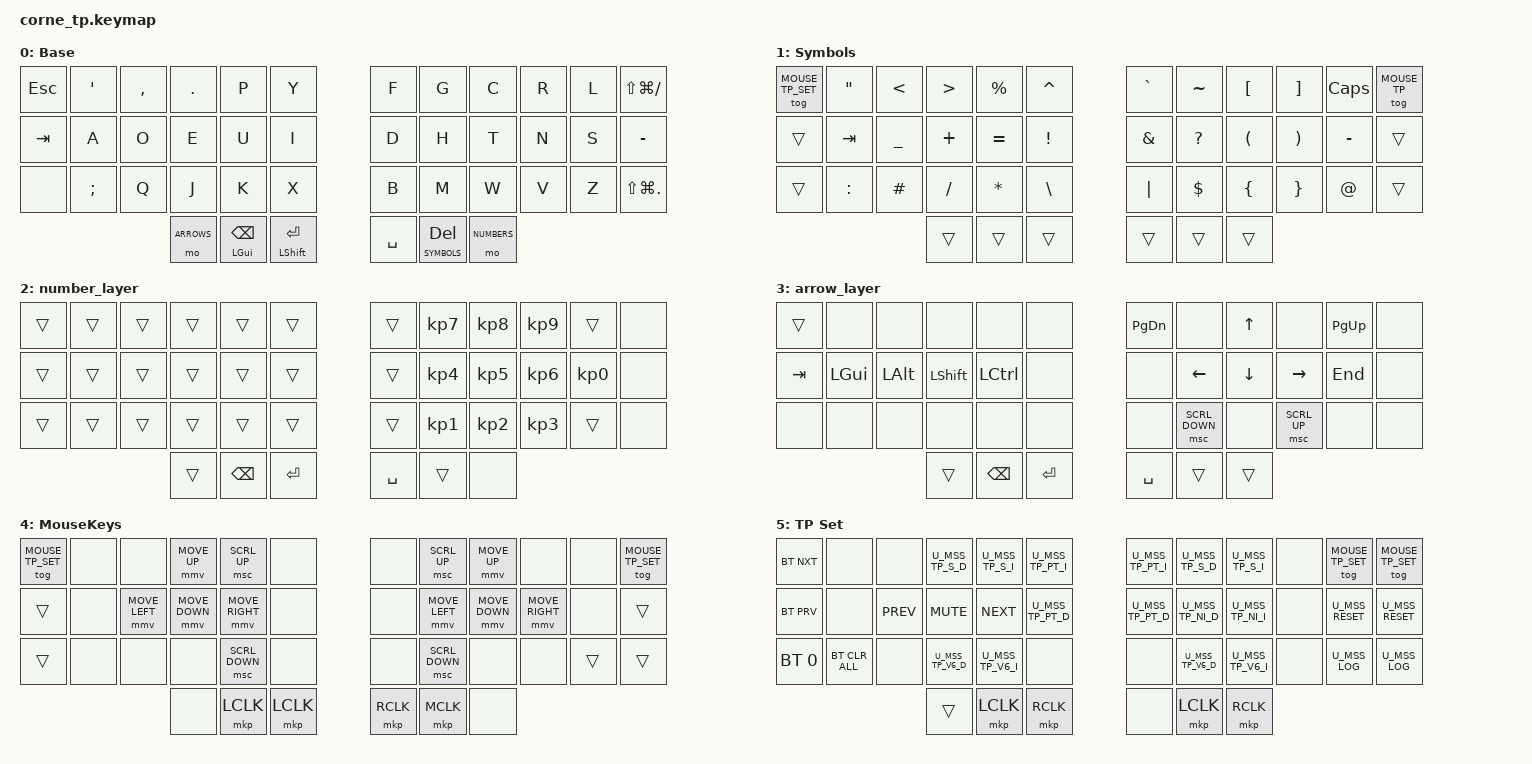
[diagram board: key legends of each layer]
/*
 * Copyright (c) 2020 The ZMK Contributors
 *
 * SPDX-License-Identifier: MIT
 */

#include <behaviors.dtsi>
#include <dt-bindings/zmk/keys.h>
#include <dt-bindings/zmk/bt.h>

#define BASE 0
#define SYMBOLS 1
#define NUMBERS 2
#define ARROWS 3
#define MOUSE_TP 4
#define MOUSE_TP_SET 5 //include things like bluetooth set, volume, next, etc. here?

/*
 * Defines to enable/disable features
 *
 * These defines allow us to conditionally enable and disable parts of the keymap config.
 *
 * For example, if we decide to build the firmware without the mouse features, we can
 * disable all the config options that rely on those forks and modules without having
 * to edit the entire keymap file manually every time.
 */

#define HAS_MOUSE_KEYS
#define HAS_MOUSE_TP

#ifdef HAS_MOUSE_KEYS
  #include <dt-bindings/zmk/mouse.h>
  #include <behaviors/mouse_keys.dtsi>
#endif  // HAS_MOUSE_KEYS

#ifdef HAS_MOUSE_TP
  // We store the trackpoint settings in a separate file
  // to make organization a little easier.
  #include "include/mouse_tp.dtsi"
#endif  // HAS_MOUSE_TP


#ifdef HAS_MOUSE_TP
  #define U_TOG_TP_SET &tog MOUSE_TP_SET
#else
  #define U_TOG_TP_SET &none
#endif  // HAS_MOUSE_TP

// Disable line-wrap in your editor to see a "visualization" of the key layouts
/ {

  keymap {
    compatible = "zmk,keymap";

    Base_layer {
      display-name = "Base";
      bindings = <
// ╭────────────────────────┬────────────────────────┬────────────────────────┬────────────────────────┬────────────────────────┬────────────────────────╮    ╭────────────────────────┬────────────────────────┬────────────────────────┬───────────────────────┬────────────────────────┬────────────────────────╮
     &kp ESC                  &kp SQT                  &kp COMMA                &kp DOT                  &kp P                    &kp Y                         &kp F                    &kp G                    &kp C                    &kp R                    &kp L                    &kp LS(LG(SLASH))
// ├────────────────────────┼────────────────────────┼────────────────────────┼────────────────────────┼────────────────────────┼────────────────────────┤    ├────────────────────────┼────────────────────────┼────────────────────────┼───────────────────────┼────────────────────────┼────────────────────────┤
     &kp TAB                  &kp A                    &kp O                    &kp E                    &kp U                    &kp I                         &kp D                    &kp H                    &kp T                    &kp N                    &kp S                    &kp MINUS
// ├────────────────────────┼────────────────────────┼────────────────────────┼────────────────────────┼────────────────────────┼────────────────────────┤    ├────────────────────────┼────────────────────────┼────────────────────────┼───────────────────────┼────────────────────────┼────────────────────────┤
     &none                    &kp SEMI                 &kp Q                    &kp J                    &kp K                    &kp X                         &kp B                    &kp M                    &kp W                    &kp V                    &kp Z                    &kp LS(LG(DOT))
// ╰────────────────────────┴────────────────────────┴────────────────────────┴────────────────────────┼────────────────────────┼────────────────────────┤    ├────────────────────────┼────────────────────────┼────────────────────────┼───────────────────────┼────────────────────────┼────────────────────────╯
                                                                                &mo ARROWS                &mt LEFT_GUI BSPC       &mt LSHIFT RET                 &kp SPACE                 &lt SYMBOLS DEL                  &mo NUMBERS
//           U_THUMB_INNER                                                                 ╰────────────────────────┴────────────────────────┴────────────────────────╯    ╰────────────────────────┴────────────────────────┴────────────────────────╯

      >;
    };


    Lower_layer {
      display-name = "Symbols";
      bindings = <
// ╭────────────────────────┬────────────────────────┬────────────────────────┬────────────────────────┬────────────────────────┬────────────────────────╮    ╭────────────────────────┬────────────────────────┬────────────────────────┬────────────────────────┬────────────────────────┬────────────────────────╮
     U_TOG_TP_SET             &kp DQT                  &kp LT                   &kp GT                   &kp PERCENT              &kp CARET                     &kp GRAVE                &kp TILDE                &kp LBKT                 &kp RBKT                 &kp CAPS                 &tog MOUSE_TP
// ├────────────────────────┼────────────────────────┼────────────────────────┼────────────────────────┼────────────────────────┼────────────────────────┤    ├────────────────────────┼────────────────────────┼────────────────────────┼────────────────────────┼────────────────────────┼────────────────────────┤
     &trans                   &kp TAB                  &kp UNDER                &kp PLUS                 &kp EQUAL                &kp EXCL                      &kp AMPS                 &kp QMARK                &kp LPAR                 &kp RPAR                 &kp MINUS                &trans
// ├────────────────────────┼────────────────────────┼────────────────────────┼────────────────────────┼────────────────────────┼────────────────────────┤    ├────────────────────────┼────────────────────────┼────────────────────────┼────────────────────────┼────────────────────────┼────────────────────────┤
     &trans                   &kp COLON                &kp HASH                 &kp SLASH                &kp STAR                 &kp BSLH                      &kp PIPE                 &kp DOLLAR               &kp LBRC                 &kp RBRC                 &kp AT                   &trans
// ╰────────────────────────┴────────────────────────┴────────────────────────┴────────────────────────┼────────────────────────┼────────────────────────┤    ├────────────────────────┼────────────────────────┼────────────────────────┼────────────────────────┴────────────────────────┼────────────────────────╯
                                                                                &trans                   &trans                   &trans                        &trans                    &trans                  &trans
//                                                                            ╰────────────────────────┴────────────────────────┴────────────────────────╯    ╰────────────────────────┴────────────────────────┴────────────────────────╯
      >;
    };

    number_layer {
     // +------------------------------------------------------------------------------------+
     // |     |     |     |     |     |         |     |  7  |  8  |  9  |     |
     // |     |     |     |     |     |         |     |  4  |  5  |  6  |  0  |
     // |     |     |     |     |     |         |     |  1  |  2  |  3  |     |
     //             | BASE|BSPC |RETURN|        |SPACE|     | none |
     // +------------------------------------------------------------------------------------+

          bindings = <
          &trans  &trans   &trans   &trans   &trans    &trans     &trans         &kp KP_NUMBER_7  &kp KP_NUMBER_8  &kp KP_NUMBER_9  &trans           &none
          &trans  &trans   &trans   &trans   &trans    &trans     &trans         &kp KP_NUMBER_4  &kp KP_NUMBER_5  &kp KP_NUMBER_6  &kp KP_NUMBER_0  &none
          &trans  &trans   &trans   &trans   &trans    &trans     &trans         &kp KP_NUMBER_1  &kp KP_NUMBER_2  &kp KP_NUMBER_3  &trans           &none
                              &trans             &kp BSPC    &kp RET    &kp SPACE      &trans           &none
          >;
     };

     arrow_layer {
               // +------------------------------------------------------------------------------------+
               // |  none  |  none  |  none  |  none  |  none  |         |  none  |  none  |  UP    |  none  |  none  |
               // |  GUI   |  ALT   |  SHFT  |  CTRL  |  TAB   |         |  HOME  |  LEFT  |  DOWN  |  RIGHT |  END   |
               // |  none  |  none  |  none  |  none  |  none  |         |  none  |  none  |  none  |  none  |  none  |
               //                           | BASE|BSPC |RETURN|         |SPACE| none | SHORTCUTS |
               // +------------------------------------------------------------------------------------+

               bindings = <
          &trans  &none     &none     &none       &none      &none      &kp PAGE_DOWN  &none           &kp UP         &none         &kp PAGE_UP  &none
          &kp TAB  &kp LGUI  &kp LALT  &kp LSHIFT  &kp LCTRL  &none    &none       &kp LEFT        &kp DOWN       &kp RIGHT     &kp END      &none
          &none  &none     &none     &none       &none      &none      &none          &msc SCRL_DOWN  &none          &msc SCRL_UP  &none        &none
                              &trans      &kp BSPC   &kp RET    &kp SPACE      &trans          &trans
          >;
     };  

#ifdef HAS_MOUSE_TP

    MouseKeys_layer {
      display-name = "MouseKeys";
      bindings = <
// ╭────────────────────────┬────────────────────────┬────────────────────────┬────────────────────────┬────────────────────────┬────────────────────────╮    ╭────────────────────────┬────────────────────────┬────────────────────────┬────────────────────────┬────────────────────────┬────────────────────────╮
     U_TOG_TP_SET             &none                    &none                    &mmv MOVE_UP             &msc SCRL_UP             &none                         &none                    &msc SCRL_UP             &mmv MOVE_UP             &none                    &none              U_TOG_TP_SET
// ├────────────────────────┼────────────────────────┼────────────────────────┼────────────────────────┼────────────────────────┼────────────────────────┤    ├────────────────────────┼────────────────────────┼────────────────────────┼────────────────────────┼────────────────────────┼────────────────────────┤
     &trans                   &none                    &mmv MOVE_LEFT           &mmv MOVE_DOWN           &mmv MOVE_RIGHT          &none                         &none                    &mmv MOVE_LEFT           &mmv MOVE_DOWN           &mmv MOVE_RIGHT          &none                     &trans
// ├────────────────────────┼────────────────────────┼────────────────────────┼────────────────────────┼────────────────────────┼────────────────────────┤    ├────────────────────────┼────────────────────────┼────────────────────────┼────────────────────────┼────────────────────────┼────────────────────────┤
     &trans                   &none                    &none                    &none                    &msc SCRL_DOWN           &none                         &none                    &msc SCRL_DOWN           &none                    &none                    &trans                    &trans
// ╰────────────────────────┴────────────────────────┴────────────────────────┴────────────────────────┼────────────────────────┼────────────────────────┤    ├────────────────────────┼────────────────────────┼────────────────────────┼────────────────────────┴────────────────────────┼────────────────────────╯
                                                                                &none                    &mkp LCLK                &mkp LCLK                     &mkp RCLK                &mkp MCLK                &none
//                                                                            ╰────────────────────────┴────────────────────────┴────────────────────────╯    ╰────────────────────────┴────────────────────────┴────────────────────────╯
      >;
    };

    // You can find the defines for the actual key press behaviors in `include/mouse_tp.dtsi`.
    MouseSettings_layer {
      display-name = "TP Set";
      bindings = <
// ╭────────────────────────┬────────────────────────┬────────────────────────┬────────────────────────┬────────────────────────┬────────────────────────╮    ╭────────────────────────┬────────────────────────┬────────────────────────┬────────────────────────┬────────────────────────┬────────────────────────╮
     &bt BT_NXT              &none                     &none                    U_MSS_TP_S_D             U_MSS_TP_S_I             U_MSS_TP_PT_I                 U_MSS_TP_PT_I            U_MSS_TP_S_D             U_MSS_TP_S_I             &none                    U_TOG_TP_SET              U_TOG_TP_SET
// ├────────────────────────┼────────────────────────┼────────────────────────┼────────────────────────┼────────────────────────┼────────────────────────┤    ├────────────────────────┼────────────────────────┼────────────────────────┼────────────────────────┼────────────────────────┼────────────────────────┤
     &bt BT_PRV              &none                     &kp C_PREV               &kp C_MUTE               &kp C_NEXT               U_MSS_TP_PT_D                 U_MSS_TP_PT_D            U_MSS_TP_NI_D            U_MSS_TP_NI_I            &none                    U_MSS_RESET               U_MSS_RESET
// ├────────────────────────┼────────────────────────┼────────────────────────┼────────────────────────┼────────────────────────┼────────────────────────┤    ├────────────────────────┼────────────────────────┼────────────────────────┼────────────────────────┼────────────────────────┼────────────────────────┤
     &bt BT_SEL 0            &bt BT_CLR_ALL            &none                    U_MSS_TP_V6_D            U_MSS_TP_V6_I            &none                         &none                    U_MSS_TP_V6_D            U_MSS_TP_V6_I            &none                    U_MSS_LOG                 U_MSS_LOG
// ╰────────────────────────┴────────────────────────┴────────────────────────┴────────────────────────┼────────────────────────┼────────────────────────┤    ├────────────────────────┼────────────────────────┼────────────────────────┼────────────────────────┴────────────────────────┼────────────────────────╯
                                                                                &trans                   &mkp LCLK                &mkp RCLK                     &none                    &mkp LCLK                &mkp RCLK
//                                                                            ╰────────────────────────┴────────────────────────┴────────────────────────╯    ╰────────────────────────┴────────────────────────┴────────────────────────╯
      >;
    };

#endif
  };
};
